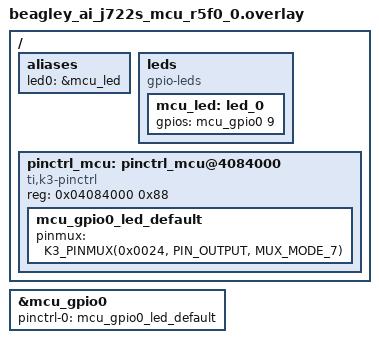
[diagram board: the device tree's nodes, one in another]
/*
 * SPDX-License-Identifier: Apache-2.0
 */

#include <zephyr/dt-bindings/gpio/gpio.h>

 / {
    aliases {
        led0 = &mcu_led;
    };

    leds {
        compatible = "gpio-leds";

        mcu_led: led_0 {
            // SoC pin B3 - Mode 7:MCU_GPIO0_9  - Address 0x04084024
            gpios = <&mcu_gpio0 9 GPIO_ACTIVE_HIGH>; // GPIO7  = CE1       - PYMNL.9             **Output**
        };
    };

    // ADDED, but does not work.
    pinctrl_mcu: pinctrl_mcu@4084000 {
        compatible = "ti,k3-pinctrl";
        reg = <0x04084000 0x88>;
        status = "okay";
    };

};

// ADDED, but does not work.
&pinctrl_mcu {
    // TODO: Pinmux seems not to be working
    // Had to execute 
    //      gpioset gpiochip0 9=1
    // on clean boot to make it flash the LED.
    mcu_gpio0_led_default: mcu_gpio0_led_default {
        pinmux = <K3_PINMUX(0x0024, PIN_OUTPUT, MUX_MODE_7)>; /* (B3) GPIO7*/
    };
};

&mcu_gpio0 {
    pinctrl-0 = <&mcu_gpio0_led_default>;
    pinctrl-names = "default";
    status = "okay";
};
